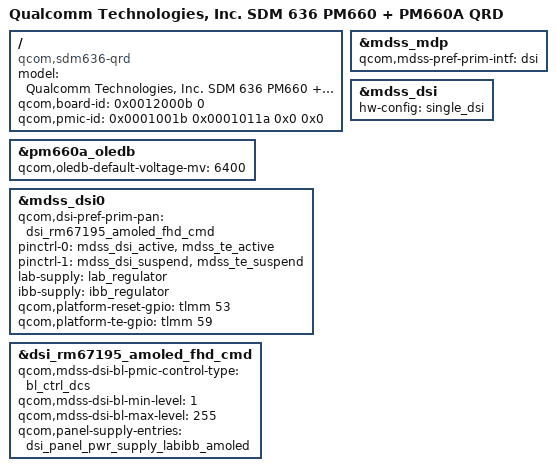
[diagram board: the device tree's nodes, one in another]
/* Copyright (c) 2017, The Linux Foundation. All rights reserved.
 *
 * This program is free software; you can redistribute it and/or modify
 * it under the terms of the GNU General Public License version 2 and
 * only version 2 as published by the Free Software Foundation.
 *
 * This program is distributed in the hope that it will be useful,
 * but WITHOUT ANY WARRANTY; without even the implied warranty of
 * MERCHANTABILITY or FITNESS FOR A PARTICULAR PURPOSE.  See the
 * GNU General Public License for more details.
 */


/dts-v1/;

#include "sdm636.dtsi"
#include "sdm636-qrd.dtsi"
#include "msm-pm660a.dtsi"

/ {
	model = "Qualcomm Technologies, Inc. SDM 636 PM660 + PM660A QRD";
	compatible = "qcom,sdm636-qrd", "qcom,sdm636", "qcom,qrd";
	qcom,board-id = <0x0012000b 0>;
	qcom,pmic-id = <0x0001001b 0x0001011a 0x0 0x0>;
};

&pm660a_oledb {
	status = "okay";
	qcom,oledb-default-voltage-mv = <6400>;
};

&mdss_mdp {
	qcom,mdss-pref-prim-intf = "dsi";
};

&mdss_dsi {
	hw-config = "single_dsi";
};

&mdss_dsi0 {
	qcom,dsi-pref-prim-pan = <&dsi_rm67195_amoled_fhd_cmd>;
	pinctrl-names = "mdss_default", "mdss_sleep";
	pinctrl-0 = <&mdss_dsi_active &mdss_te_active>;
	pinctrl-1 = <&mdss_dsi_suspend &mdss_te_suspend>;
	lab-supply = <&lab_regulator>;
	ibb-supply = <&ibb_regulator>;
	qcom,platform-reset-gpio = <&tlmm 53 0>;
	qcom,platform-te-gpio = <&tlmm 59 0>;
};

&dsi_rm67195_amoled_fhd_cmd {
	qcom,mdss-dsi-bl-pmic-control-type = "bl_ctrl_dcs";
	qcom,mdss-dsi-bl-min-level = <1>;
	qcom,mdss-dsi-bl-max-level = <255>;
	qcom,panel-supply-entries = <&dsi_panel_pwr_supply_labibb_amoled>;
};
